# PIC32CM5112SG00100 device description
Architecture: CORTEX-M23; Family: PIC32CM; Series: PIC32CMSG00
Registers are 32-bit, read-write, reset 0x0 unless marked. A register's access mark holds for its fields unless they carry their own. Offsets are from the block's base; [hi:lo] are bit positions; {n}, {i} and the like mark numbered series; 'fields as' and 'values as' point back to an identical list.

## CAN_MRAM_TXBE — Control Area Network
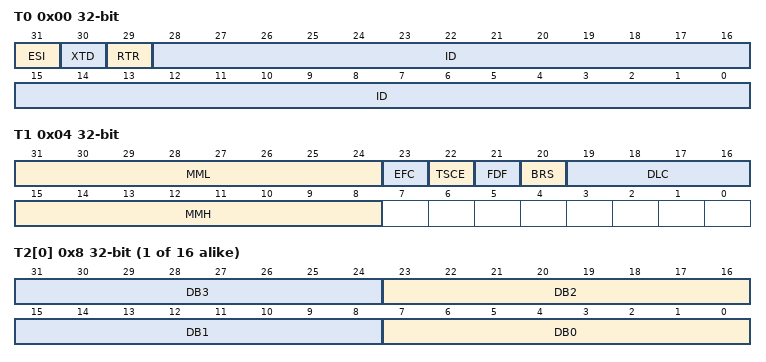
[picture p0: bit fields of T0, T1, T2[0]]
0x00 T0 — Tx Buffer Element 0
  [31] ESI — Error State Indicator
  [30] XTD — Extended Identifier
  [29] RTR — Remote Transmission Request
  [28:0] ID — Identifier
0x04 T1 — Tx Buffer Element 1
  [31:24] MML — Message Marker Lower Byte
  [23] EFC — Event FIFO Control
  [22] TSCE — Time Stamp Capture Enable for TSU
  [21] FDF — FD Format
  [20] BRS — Bit Rate Search
  [19:16] DLC — Identifier
  [15:8] MMH — Message Marker Higher Byte
{0x8+4i} T2[{i}] (i=0..15) — Tx Buffer Element Data
  [8n+7:8n] DB{n} (n=0..3) — Data Byte {n}

## CAN_MRAM_TXEFE — Control Area Network
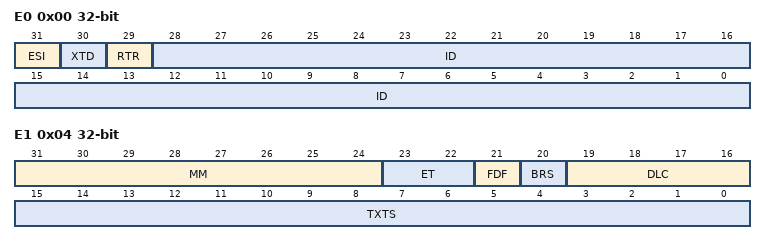
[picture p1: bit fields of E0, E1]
0x00 E0 — Tx Event FIFO Element 0
  [31] ESI — Error State Indicator
  [30] XTD — Extended Indentifier
  [29] RTR — Remote Transmission Request
  [28:0] ID — Identifier
0x04 E1 — Tx Event FIFO Element 1
  [31:24] MM — Message Marker
  [23:22] ET — Event Type
    1=TXE (Tx event); 2=TXC (Transmission in spite of cancellation)
  [21] FDF — FD Format
  [20] BRS — Bit Rate Search
  [19:16] DLC — Data Length Code
  [15:0] TXTS — Tx Timestamp

## CAN_MRAM_XIDFE — Control Area Network
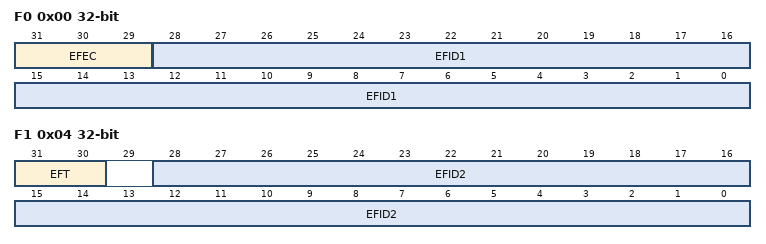
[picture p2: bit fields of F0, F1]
0x00 F0 — Extended Message ID Filter Element 0
  [31:29] EFEC — Extended Filter Element Configuration
    0=DISABLE (Disable filter element); 1=STF0M (Store in Rx FIFO 0 if filter match); 2=STF1M (Store in Rx FIFO 1 if filter match); 3=REJECT (Reject ID if filter match); 4=PRIORITY (Set priority if filter match); 5=PRIF0M (Set priority and store in FIFO 0 if filter match); 6=PRIF1M (Set priority and store in FIFO 1 if filter match); 7=STRXBUF (Store into Rx Buffer)
  [28:0] EFID1 — Extended Filter ID 1
0x04 F1 — Extended Message ID Filter Element 1
  [31:30] EFT — Extended Filter Type
    0=RANGEM (Range filter from EFID1 to EFID2); 1=DUAL (Dual ID filter for EFID1 or EFID2); 2=CLASSIC (Classic filter); 3=RANGE (Range filter from EFID1 to EFID2 with no XIDAM mask)
  [28:0] EFID2 — Extended Filter ID 2

## CCL — Configurable Custom Logic
Instances: CCL0 0x4482E000, CCL1 0x44830000
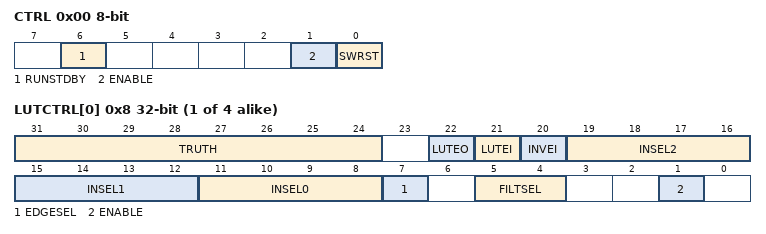
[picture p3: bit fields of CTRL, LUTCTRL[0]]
0x00 CTRL 8-bit — Control
  [6] RUNSTDBY — Run in Standby
    0=DISABLE (Generic clock is not required in standby sleep mode); 1=ENABLE (Generic clock is required in standby sleep mode)
  [1] ENABLE
    0=DISABLE (The peripheral is disabled); 1=ENABLE (The peripheral is enabled)
  [0] SWRST — Software Reset
    0=DISABLE (The peripheral is not reset); 1=ENABLE (The peripheral is reset)
{0x4+i} SEQCTRL[{i}] (i=0..1) 8-bit — SEQ Control x
  [3:0] SEQSEL — Sequential Selection
    0=DISABLE (Sequential logic is disabled); 1=DFF (D flip flop); 2=JK (JK flip flop); 3=LATCH (D latch); 4=RS (RS latch)
{0x8+4i} LUTCTRL[{i}] (i=0..3) — LUT Control x
  [31:24] TRUTH — Truth Value
  [22] LUTEO — LUT Event Output Enable
    0=DISABLE (LUT event output is disabled); 1=ENABLE (LUT event output is enabled)
  [21] LUTEI — LUT Event Input Enable
    0=DISABLE (LUT incoming event is disabled); 1=ENABLE (LUT incoming event is enabled)
  [20] INVEI — Inverted Event Input Enable
    0=NORMAL (Incoming event is not inverted); 1=INVERTED (Incoming event is inverted)
  [19:16] INSEL2 — Input Selection 2
    0=MASK (Masked input); 1=FEEDBACK (Feedback input source); 2=LINK (Linked LUT input source); 3=EVENT (Event input source); 4=IO (I/O pin input source); {v}=PERSEL{v-5} (Peripheral {v-5} input source) (v=5..10); 11=ASYNCEVENT (Asynchronous event input source. The EVENT input will bypass edge detection logic.)
  [15:12] INSEL1 — Input Selection 1
    values as INSEL2
  [11:8] INSEL0 — Input Selection 0
    values as INSEL2
  [7] EDGESEL — Edge Selection
    0=DISABLE (Edge detector is disabled); 1=ENABLE (Edge detector is enabled)
  [5:4] FILTSEL — Filter Selection
    0=DISABLE (Filter disabled); 1=SYNCH (Synchronizer enabled); 2=FILTER (Filter enabled)
  [1] ENABLE — LUT Enable
    0=DISABLE (LUT block is disabled); 1=ENABLE (LUT block is enabled)
